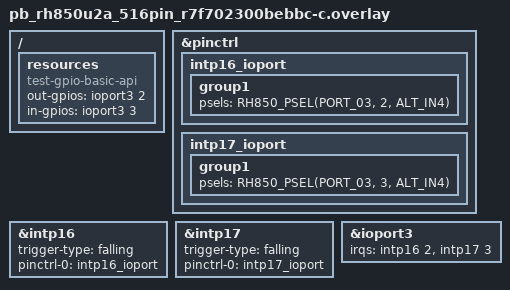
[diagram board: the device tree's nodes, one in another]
/*
 * Copyright (c) 2026 Renesas Electronics Corporation
 * SPDX-License-Identifier: Apache-2.0
 */

/ {
	resources {
		compatible = "test-gpio-basic-api";
		out-gpios = <&ioport3 2 GPIO_ACTIVE_HIGH>;
		in-gpios = <&ioport3 3 GPIO_ACTIVE_HIGH>;
	};
};

&pinctrl {
	intp16_ioport: intp16_ioport {
		group1 {
			psels = <RH850_PSEL(PORT_03, 2, ALT_IN4)>;
		};
	};

	intp17_ioport: intp17_ioport {
		group1 {
			psels = <RH850_PSEL(PORT_03, 3, ALT_IN4)>;
		};
	};
};

&intp16 {
	trigger-type = "falling";
	pinctrl-0 = <&intp16_ioport>;
	pinctrl-names = "default";
	status = "okay";
};

&intp17 {
	trigger-type = "falling";
	pinctrl-0 = <&intp17_ioport>;
	pinctrl-names = "default";
	status = "okay";
};

&ioport3 {
	irqs = <&intp16 2>, <&intp17 3>;
	status = "okay";
};
